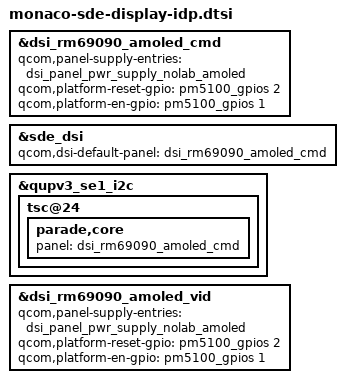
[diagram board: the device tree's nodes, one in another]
#include "monaco-sde-display.dtsi"

&dsi_rm69090_amoled_cmd {
	qcom,panel-supply-entries = <&dsi_panel_pwr_supply_nolab_amoled>;
	qcom,platform-reset-gpio = <&pm5100_gpios 2 0>;
	qcom,platform-en-gpio = <&pm5100_gpios 1 0>;
};

&sde_dsi {
	qcom,dsi-default-panel = <&dsi_rm69090_amoled_cmd>;
};

&qupv3_se1_i2c {
	tsc@24 {
		parade,core {
		panel = <&dsi_rm69090_amoled_cmd>;
		};
	};
};

&dsi_rm69090_amoled_vid {
	qcom,panel-supply-entries = <&dsi_panel_pwr_supply_nolab_amoled>;
	qcom,platform-reset-gpio = <&pm5100_gpios 2 0>;
	qcom,platform-en-gpio = <&pm5100_gpios 1 0>;
};
